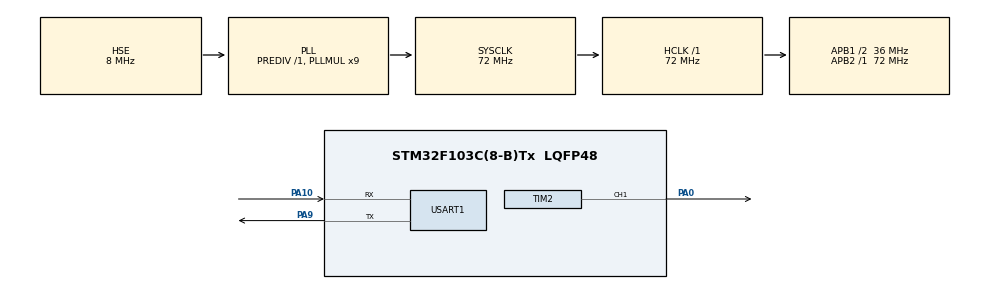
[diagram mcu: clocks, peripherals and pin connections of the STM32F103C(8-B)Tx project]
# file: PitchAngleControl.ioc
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Mcu.Family=STM32F1
Mcu.Name=STM32F103C(8-B)Tx
Mcu.Package=LQFP48
NVIC.PriorityGroup=NVIC_PRIORITYGROUP_4
NVIC.USART1_IRQn=true\:0\:0\:false\:false\:true\:true\:true\:true
PA0-WKUP.Signal=S_TIM2_CH1_ETR
PA10.Mode=Asynchronous
PA10.Signal=USART1_RX
PA13.Mode=JTAG_4_pins
PA13.Signal=SYS_JTMS-SWDIO
PA14.Mode=JTAG_4_pins
PA14.Signal=SYS_JTCK-SWCLK
PA15.Mode=JTAG_4_pins
PA15.Signal=SYS_JTDI
PA9.Mode=Asynchronous
PA9.Signal=USART1_TX
PB3.Mode=JTAG_4_pins
PB3.Signal=SYS_JTDO-TRACESWO
PD0-OSC_IN.Mode=HSE-External-Oscillator
PD0-OSC_IN.Signal=RCC_OSC_IN
PD1-OSC_OUT.Mode=HSE-External-Oscillator
PD1-OSC_OUT.Signal=RCC_OSC_OUT
ProjectManager.HeapSize=0x200
ProjectManager.StackSize=0x400
ProjectManager.TargetToolchain=STM32CubeIDE
RCC.AHBFreq_Value=72000000
RCC.APB1CLKDivider=RCC_HCLK_DIV2
RCC.APB1Freq_Value=36000000
RCC.APB1TimFreq_Value=72000000
RCC.APB2Freq_Value=72000000
RCC.APB2TimFreq_Value=72000000
RCC.HCLKFreq_Value=72000000
RCC.PLLMUL=RCC_PLL_MUL9
RCC.PLLSourceVirtual=RCC_PLLSOURCE_HSE
RCC.SYSCLKFreq_VALUE=72000000
RCC.SYSCLKSource=RCC_SYSCLKSOURCE_PLLCLK
RCC.USBFreq_Value=72000000
SH.S_TIM2_CH1_ETR.0=TIM2_CH1,PWM Generation1 CH1
TIM2.Channel-PWM\ Generation1\ CH1=TIM_CHANNEL_1
TIM2.Period=19999
TIM2.Prescaler=71
USART1.VirtualMode=VM_ASYNC
board=custom

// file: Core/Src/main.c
/* USER CODE BEGIN Header */
/**
  ******************************************************************************
  * @file           : main.c
  * @brief          : Main program body
  ******************************************************************************
  * @attention
  *
  * Copyright (c) 2025 STMicroelectronics.
  * All rights reserved.
  *
  * This software is licensed under terms that can be found in the LICENSE file
  * in the root directory of this software component.
  * If no LICENSE file comes with this software, it is provided AS-IS.
  *
  ******************************************************************************
  */
/* USER CODE END Header */
#include "main.h"

/* USER CODE BEGIN Includes */
#include "string.h"
#include <stdlib.h>
/* USER CODE END Includes */

/* USER CODE BEGIN PM */
#define MAX_ANGLE_VALUE 270.0  // 最大允许角度值
#define RX_BUFFER_SIZE 128     // 串口接收缓冲区大小

/* USER CODE END PM */

TIM_HandleTypeDef htim2;

UART_HandleTypeDef huart1;

/* USER CODE BEGIN PV */

const uint32_t PWM_FREQ = 50;  // 50Hz舵机标准信号
const uint32_t TIM_CLK = 72000000;  // 72MHz系统时钟
const float MIN_PULSE = 0.5;   // 0.5ms (0°位置)
const float MAX_PULSE = 2.5;   // 2.5ms (180°位置)

// 全局变量定义
char rxBuffer[RX_BUFFER_SIZE]; // 接收缓冲区
uint8_t rxIndex = 0;           // 缓冲区索引
volatile uint8_t rxComplete = 0; // 接收完成标志
float pitchAngle = 0.0;        // 存储解析后的俯仰角度

/* USER CODE END PV */

void SystemClock_Config(void);
static void MX_GPIO_Init(void);
static void MX_TIM2_Init(void);
static void MX_USART1_UART_Init(void);
/* USER CODE BEGIN PFP */

void Set_Servo_Angle(float angle);
/* USER CODE END PFP */

/* USER CODE BEGIN 0 */
// 串口接收中断回调函数
void HAL_UART_RxCpltCallback(UART_HandleTypeDef *huart) {
  if (huart->Instance == USART1) {
    // 检查是否收到完整指令（以换行符结束）
    if (rxBuffer[rxIndex] == 'x') {
      rxBuffer[rxIndex] = '\0'; // 替换结束符
      rxComplete = 1;           // 设置接收完成标志
      rxIndex = 0;              // 重置索引
    }
    else {
      rxIndex++;  // 移动到下一个缓冲位置

      // 防止缓冲区溢出
      if (rxIndex >= RX_BUFFER_SIZE - 1) {
        rxIndex = 0; // 溢出时重置缓冲区
      }
    }

    // 重新启用接收中断
    HAL_UART_Receive_IT(&huart1, (uint8_t*)&rxBuffer[rxIndex], 1);
  }
}

// 解析角度指令函数
void ParseAngleCommand(void) {
  // 临时变量用于解析
  char *token;
  char tempBuffer[RX_BUFFER_SIZE];

  // 复制接收缓冲到临时变量
  strncpy(tempBuffer, rxBuffer, RX_BUFFER_SIZE);

  // 查找"ANGLE:"指令前缀
  token = strtok(tempBuffer, ":");
  if (token != NULL && strcmp(token, "ANGLE") == 0) {
    // 提取角度值部分
    token = strtok(NULL, ":");
    if (token != NULL) {
      // 转换为浮点数
      float value = atof(token);

      // 验证角度范围
      if (value >= 0 && value <= MAX_ANGLE_VALUE) {
        pitchAngle = value; // 更新全局角度值
        // 此处可添加舵机控制函数调用
        Set_Servo_Angle(pitchAngle);
        char doneMsg[] = "PITCH_DONE\r\n";
        HAL_UART_Transmit(&huart1, (uint8_t*)doneMsg, strlen(doneMsg), HAL_MAX_DELAY);
      }
    }
  }

  // 清空接收完成标志
  rxComplete = 0;
}

// 设置舵机角度 (0°-180°)
void Set_Servo_Angle(float angle) {
  // 限制角度范围
  if (angle < 0) angle = 0;
  if (angle > 270) angle = 270;

  // 计算脉宽时间
  float pulse_width = MIN_PULSE + (angle / 270.0) * (MAX_PULSE - MIN_PULSE);

  // 计算对应的寄存器值 (ARR=自动重装载值)
  uint32_t pulse = (pulse_width / 1000.0) * TIM_CLK / htim2.Init.Prescaler;
  __HAL_TIM_SET_COMPARE(&htim2, TIM_CHANNEL_1, pulse);
}

/* USER CODE END 0 */

int main(void)
{

  /* MCU Configuration--------------------------------------------------------*/

  /* Reset of all peripherals, Initializes the Flash interface and the Systick. */
  HAL_Init();

  /* Configure the system clock */
  SystemClock_Config();

  /* Initialize all configured peripherals */
  MX_GPIO_Init();
  MX_TIM2_Init();
  MX_USART1_UART_Init();
  /* USER CODE BEGIN 2 */
  // 启动PWM通道
  HAL_TIM_PWM_Start(&htim2, TIM_CHANNEL_1);
  // 启用串口接收中断
  HAL_UART_Receive_IT(&huart1, (uint8_t*)&rxBuffer[rxIndex], 1);
  // 示例：旋转舵机到45°位置
  Set_Servo_Angle(90);
  /* USER CODE END 2 */

  /* Infinite loop */
  /* USER CODE BEGIN WHILE */
  while (1)
  {
	// 检查串口接收是否完成
	if (rxComplete) {
	  ParseAngleCommand(); // 解析角度指令
	}

	// 主循环延时（可根据需求调整）
	HAL_Delay(10);
	// 主循环延时（可根据需求调整）
	//HAL_Delay(1);
    /* USER CODE END WHILE */

  }
}

void SystemClock_Config(void)
{
  RCC_OscInitTypeDef RCC_OscInitStruct = {0};
  RCC_ClkInitTypeDef RCC_ClkInitStruct = {0};

  /** Initializes the RCC Oscillators according to the specified parameters
  * in the RCC_OscInitTypeDef structure.
  */
  RCC_OscInitStruct.OscillatorType = RCC_OSCILLATORTYPE_HSE;
  RCC_OscInitStruct.HSEState = RCC_HSE_ON;
  RCC_OscInitStruct.HSEPredivValue = RCC_HSE_PREDIV_DIV1;
  RCC_OscInitStruct.HSIState = RCC_HSI_ON;
  RCC_OscInitStruct.PLL.PLLState = RCC_PLL_ON;
  RCC_OscInitStruct.PLL.PLLSource = RCC_PLLSOURCE_HSE;
  RCC_OscInitStruct.PLL.PLLMUL = RCC_PLL_MUL9;
  if (HAL_RCC_OscConfig(&RCC_OscInitStruct) != HAL_OK)
  {
    Error_Handler();
  }

  /** Initializes the CPU, AHB and APB buses clocks
  */
  RCC_ClkInitStruct.ClockType = RCC_CLOCKTYPE_HCLK|RCC_CLOCKTYPE_SYSCLK
                              |RCC_CLOCKTYPE_PCLK1|RCC_CLOCKTYPE_PCLK2;
  RCC_ClkInitStruct.SYSCLKSource = RCC_SYSCLKSOURCE_PLLCLK;
  RCC_ClkInitStruct.AHBCLKDivider = RCC_SYSCLK_DIV1;
  RCC_ClkInitStruct.APB1CLKDivider = RCC_HCLK_DIV2;
  RCC_ClkInitStruct.APB2CLKDivider = RCC_HCLK_DIV1;

  if (HAL_RCC_ClockConfig(&RCC_ClkInitStruct, FLASH_LATENCY_2) != HAL_OK)
  {
    Error_Handler();
  }
}

static void MX_TIM2_Init(void)
{

  TIM_MasterConfigTypeDef sMasterConfig = {0};
  TIM_OC_InitTypeDef sConfigOC = {0};

  htim2.Instance = TIM2;
  htim2.Init.Prescaler = 71;
  htim2.Init.CounterMode = TIM_COUNTERMODE_UP;
  htim2.Init.Period = 19999;
  htim2.Init.ClockDivision = TIM_CLOCKDIVISION_DIV1;
  htim2.Init.AutoReloadPreload = TIM_AUTORELOAD_PRELOAD_DISABLE;
  if (HAL_TIM_PWM_Init(&htim2) != HAL_OK)
  {
    Error_Handler();
  }
  sMasterConfig.MasterOutputTrigger = TIM_TRGO_RESET;
  sMasterConfig.MasterSlaveMode = TIM_MASTERSLAVEMODE_DISABLE;
  if (HAL_TIMEx_MasterConfigSynchronization(&htim2, &sMasterConfig) != HAL_OK)
  {
    Error_Handler();
  }
  sConfigOC.OCMode = TIM_OCMODE_PWM1;
  sConfigOC.Pulse = 0;
  sConfigOC.OCPolarity = TIM_OCPOLARITY_HIGH;
  sConfigOC.OCFastMode = TIM_OCFAST_DISABLE;
  if (HAL_TIM_PWM_ConfigChannel(&htim2, &sConfigOC, TIM_CHANNEL_1) != HAL_OK)
  {
    Error_Handler();
  }
  HAL_TIM_MspPostInit(&htim2);

}

static void MX_USART1_UART_Init(void)
{

  huart1.Instance = USART1;
  huart1.Init.BaudRate = 115200;
  huart1.Init.WordLength = UART_WORDLENGTH_8B;
  huart1.Init.StopBits = UART_STOPBITS_1;
  huart1.Init.Parity = UART_PARITY_NONE;
  huart1.Init.Mode = UART_MODE_TX_RX;
  huart1.Init.HwFlowCtl = UART_HWCONTROL_NONE;
  huart1.Init.OverSampling = UART_OVERSAMPLING_16;
  if (HAL_UART_Init(&huart1) != HAL_OK)
  {
    Error_Handler();
  }

}

static void MX_GPIO_Init(void)
{

  /* GPIO Ports Clock Enable */
  __HAL_RCC_GPIOD_CLK_ENABLE();
  __HAL_RCC_GPIOA_CLK_ENABLE();
  __HAL_RCC_GPIOB_CLK_ENABLE();

}

void Error_Handler(void)
{
  __disable_irq();
  while (1)
  {
  }
}
